# ATSAMA5D27 register map
Vendor: Microchip Technology Inc.; File version: 1.0
CPU: CA5 r0p1, little endian, no MPU, no FPU, 4 interrupt priority bits
Address unit: 32 bits
Registers are 32-bit, read-write, reset 0x0 unless marked. A register's access mark holds for its fields unless they carry their own. Offsets are from the block's base; [hi:lo] are bit positions; {n}, {i} and the like mark numbered series.

## TRNG — True Random Number Generator
Base 0xFC01C000
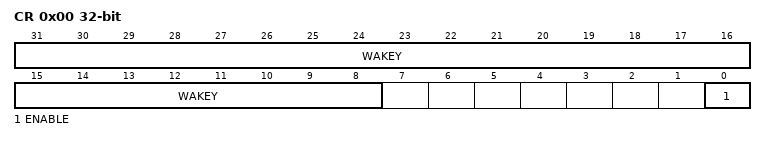
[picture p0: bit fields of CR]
0x00 CR wo — Control Register
  [31:8] WAKEY rw — Register Write Access Key
    0x524E47=PASSWD (Writing any other value in this field aborts the write operation.)
  [0] ENABLE rw — Enables the TRNG to Provide Random Values
0x10 IER wo — Interrupt Enable Register
  [0] DATRDY rw — Data Ready Interrupt Enable
0x14 IDR wo — Interrupt Disable Register
  [0] DATRDY rw — Data Ready Interrupt Disable
0x18 IMR ro — Interrupt Mask Register
  [0] DATRDY rw — Data Ready Interrupt Mask
0x1C ISR ro — Interrupt Status Register
  [0] DATRDY rw — Data Ready (cleared on read)
0x50 ODATA ro — Output Data Register
  [31:0] ODATA rw — Output Data

## UDPHS — USB High Speed Device Port
Base 0xFC02C000
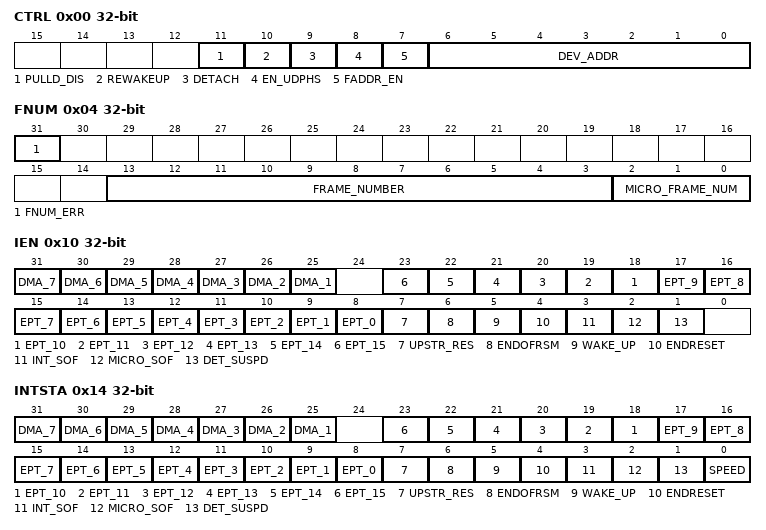
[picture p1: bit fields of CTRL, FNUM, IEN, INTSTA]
0x00 CTRL — UDPHS Control Register
  [11] PULLD_DIS — Pulldown Disable (cleared upon USB reset)
  [10] REWAKEUP — Send Remote Wakeup (cleared upon USB reset)
  [9] DETACH — Detach Command
  [8] EN_UDPHS — UDPHS Enable
  [7] FADDR_EN — Function Address Enable (cleared upon USB reset)
  [6:0] DEV_ADDR — UDPHS Address (cleared upon USB reset)
0x04 FNUM ro — UDPHS Frame Number Register
  [31] FNUM_ERR rw — Frame Number CRC Error (cleared upon USB reset)
  [13:3] FRAME_NUMBER rw — Frame Number as defined in the Packet Field Formats (cleared upon USB reset)
  [2:0] MICRO_FRAME_NUM rw — Microframe Number (cleared upon USB reset)
0x10 IEN — UDPHS Interrupt Enable Register
  [n+24] DMA_{n} (n=1..7) — DMA Channel {n} Interrupt Enable (cleared upon USB reset)
  [n+8] EPT_{n} (n=0..15) — Endpoint {n} Interrupt Enable (cleared upon USB reset)
  [7] UPSTR_RES — Upstream Resume Interrupt Enable (cleared upon USB reset)
  [6] ENDOFRSM — End Of Resume Interrupt Enable (cleared upon USB reset)
  [5] WAKE_UP — Wake Up CPU Interrupt Enable (cleared upon USB reset)
  [4] ENDRESET — End Of Reset Interrupt Enable (cleared upon USB reset)
  [3] INT_SOF — SOF Interrupt Enable (cleared upon USB reset)
  [2] MICRO_SOF — Micro-SOF Interrupt Enable (cleared upon USB reset)
  [1] DET_SUSPD — Suspend Interrupt Enable (cleared upon USB reset)
0x14 INTSTA ro — UDPHS Interrupt Status Register
  [n+24] DMA_{n} rw (n=1..7) — DMA Channel {n} Interrupt
  [n+8] EPT_{n} rw (n=0..15) — Endpoint {n} Interrupt (cleared upon USB reset)
  [7] UPSTR_RES rw — Upstream Resume Interrupt
  [6] ENDOFRSM rw — End Of Resume Interrupt
  [5] WAKE_UP rw — Wake Up CPU Interrupt
  [4] ENDRESET rw — End Of Reset Interrupt
  [3] INT_SOF rw — Start Of Frame Interrupt
  [2] MICRO_SOF rw — Micro Start Of Frame Interrupt
  [1] DET_SUSPD rw — Suspend Interrupt
  [0] SPEED rw — Speed Status
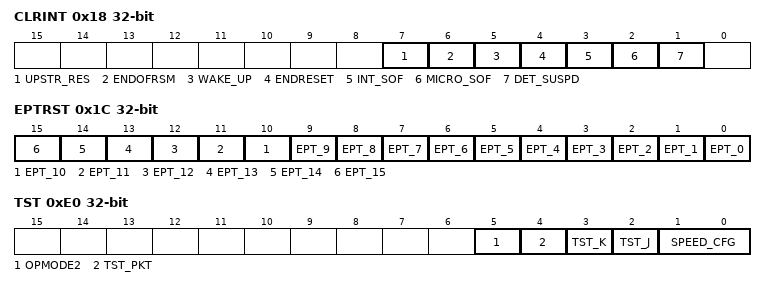
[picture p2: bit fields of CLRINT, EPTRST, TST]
0x18 CLRINT wo — UDPHS Clear Interrupt Register
  [7] UPSTR_RES rw — Upstream Resume Interrupt Clear
  [6] ENDOFRSM rw — End Of Resume Interrupt Clear
  [5] WAKE_UP rw — Wake Up CPU Interrupt Clear
  [4] ENDRESET rw — End Of Reset Interrupt Clear
  [3] INT_SOF rw — Start Of Frame Interrupt Clear
  [2] MICRO_SOF rw — Micro Start Of Frame Interrupt Clear
  [1] DET_SUSPD rw — Suspend Interrupt Clear
0x1C EPTRST wo — UDPHS Endpoints Reset Register
  [n] EPT_{n} rw (n=0..15) — Endpoint {n} Reset
0xE0 TST — UDPHS Test Register
  [5] OPMODE2
  [4] TST_PKT — Test Packet Mode
  [3] TST_K — Test K Mode
  [2] TST_J — Test J Mode
  [1:0] SPEED_CFG — Speed Configuration
    0=NORMAL (Normal mode: The macro is in Full Speed mode, ready to make a High Speed identification, if the host supports it and then to automatically switch to High Speed mode.); 2=HIGH_SPEED (Force High Speed: Set this value to force the hardware to work in High Speed mode. Only for debug or test purpose.); 3=FULL_SPEED (Force Full Speed: Set this value to force the hardware to work only in Full Speed mode. In this configuration, the macro will not respond to a High Speed reset handshake.)
0xEC ADDRSIZE ro — UDPHS IP Address Size Register
  [31:0] ADDRSIZE rw — Peripheral Bus Address Size
0xF0 IPNAME ro — UDPHS IP Name1 Register
  [31:0] IPNAME rw — IP Name in ASCII Format
0xF8 FEATURES ro — UDPHS Features Register

## WDT — Watchdog Timer
Base 0xF8048040
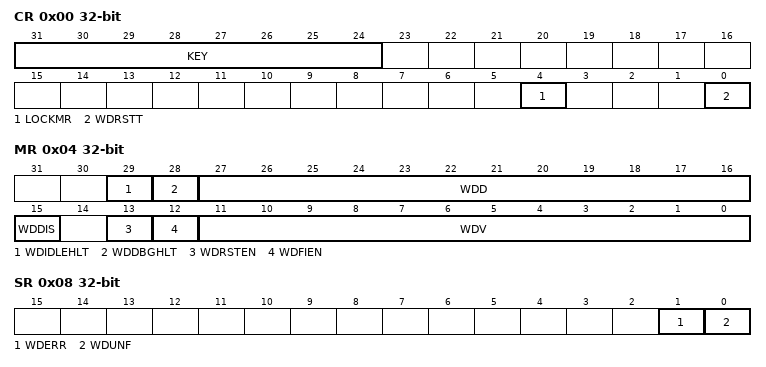
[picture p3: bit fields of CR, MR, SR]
0x00 CR wo — Control Register
  [31:24] KEY rw — Password
    165=PASSWD (Writing any other value in this field aborts the write operation.)
  [4] LOCKMR rw — Lock Mode Register Write Access
  [0] WDRSTT rw — Watchdog Restart
0x04 MR — Mode Register
  [29] WDIDLEHLT — Watchdog Idle Halt
  [28] WDDBGHLT — Watchdog Debug Halt
  [27:16] WDD — Watchdog Delta Value
  [15] WDDIS — Watchdog Disable
  [13] WDRSTEN — Watchdog Reset Enable
  [12] WDFIEN — Watchdog Fault Interrupt Enable
  [11:0] WDV — Watchdog Counter Value
0x08 SR ro — Status Register
  [1] WDERR rw — Watchdog Error (cleared on read)
  [0] WDUNF rw — Watchdog Underflow (cleared on read)
